# RockChip_RK3588 register map
Vendor: RockChip Electronics Co., Ltd.; Series: RK3588; File version: 0.1
Registers are 32-bit, read-write, no defined reset value unless marked. A register's access mark holds for its fields unless they carry their own. Offsets are from the block's base; [hi:lo] are bit positions; {n}, {i} and the like mark numbered series.

## GRF_DSU
Base 0xFD598000
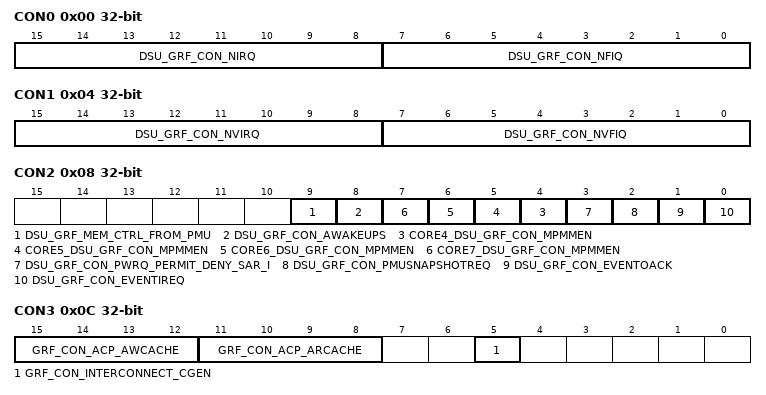
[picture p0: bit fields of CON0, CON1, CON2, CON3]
0x00 CON0 — DSU Control Register 0
  [15:8] DSU_GRF_CON_NIRQ — GRF generate a nirq for each core, for debug usage only
  [7:0] DSU_GRF_CON_NFIQ — GRF generate a nifq for each core, for debug usage only
0x04 CON1 — DSU Control Register 1
  [15:8] DSU_GRF_CON_NVIRQ — GRF generate a nvirq for each core, for debug usage only
  [7:0] DSU_GRF_CON_NVFIQ — GRF generate a nvifq for each core, for debug usage only
0x08 CON2 — DSU Control Register 2
  [9] DSU_GRF_MEM_CTRL_FROM_PMU
    1=PMU (Dsu mem cfg driven by pmu); 0=GRF (Dsu mem cfg driven by grf)
  [8] DSU_GRF_CON_AWAKEUPS
    1=WAKE (Wake acp slave interface); 0=DONT_WAKE (Not wake acp)
  [n] CORE{n}_DSU_GRF_CON_MPMMEN (n=4..7)
    1=ENABLE (Enable max power control for A76); 0=DISABLE
  [3] DSU_GRF_CON_PWRQ_PERMIT_DENY_SAR_I
    1=DENY (Stream adb400 will deny a power request); 0=ACCEPT (Stream adb400 will accept a power request)
  [2] DSU_GRF_CON_PMUSNAPSHOTREQ
    1=SEND (Send a pmu snapshot request to DSU); 0=DONT_SEND (Not send)
  [1] DSU_GRF_CON_EVENTOACK
    1=SEND (Send evento acknowledge to DSU); 0=DONT_SEND (Not send)
  [0] DSU_GRF_CON_EVENTIREQ
    1=SEND (Send eventi request to DSU); 0=DONT_SEND (Not send)
0x0C CON3 — DSU Control Register 3
  [15:12] GRF_CON_ACP_AWCACHE — Awcache control bit for acp
  [11:8] GRF_CON_ACP_ARCACHE — Arcache ctrl bit for acp
  [5] GRF_CON_INTERCONNECT_CGEN
    1=ENABLE (Interconnect clock gate enable); 0=DISABLE
0x10 CON4 — DSU Control Register 4
  [15:0] SYS_GRF_CON_ASTARTMP — Start address of MP master
0x14 CON5 — DSU Control Register 5
  [15:0] SYS_GRF_CON_AENDMP — End address for MP master
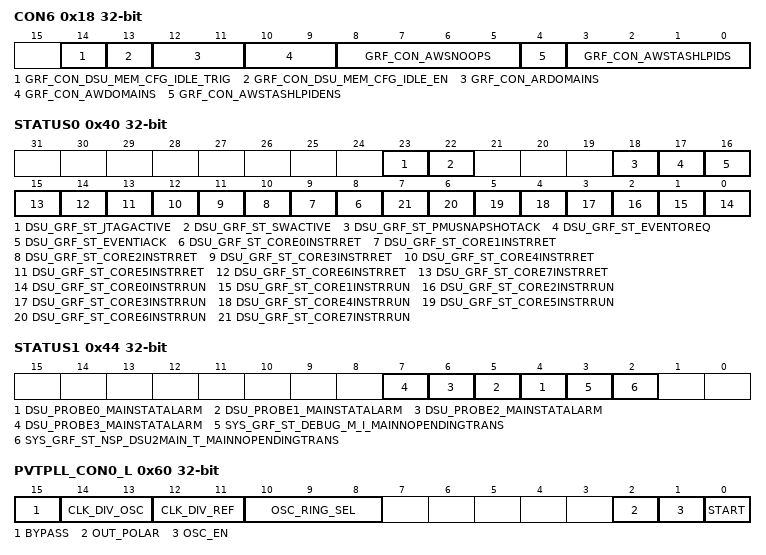
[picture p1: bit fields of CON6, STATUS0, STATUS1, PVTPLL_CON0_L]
0x18 CON6 — DSU Control Register 6
  [14] GRF_CON_DSU_MEM_CFG_IDLE_TRIG — A 0 to 1 trigger of grf_con_dsu_mem_cfg_idle_trig will cause a mem_cfg change when grf_con_dsu_mem_cfg_idle_en equals to 1.
  [13] GRF_CON_DSU_MEM_CFG_IDLE_EN
    0=SW_IMMEDIATELY (Mem_cfg is changed by software immediately); 1=ALL_WFI (Mem_cfg is changed when all cpu in wfi)
  [12:11] GRF_CON_ARDOMAINS — Ardomain control for ACP
  [10:9] GRF_CON_AWDOMAINS — Awdomain control for ACP
  [8:5] GRF_CON_AWSNOOPS — Awsnoop ctrl for ACP
  [4] GRF_CON_AWSTASHLPIDENS — AW stashlpiden for ACP
  [3:0] GRF_CON_AWSTASHLPIDS — AW stashlpid for ACP
0x20 MEM_CFG_HSSPRF_L — Memory Configuration Register For HSSPRF
  [15:0] GRF_DSU_MEM_CFG_HSSPRF_L — bit 0: TEST1 bit 1: TEST_RNM bit 4~2: RM bit 5: WMD bit 7: LS bit 13~12: RA
0x28 MEM_CFG_HSDPRF_L — Memory Configuration Register For HSDPRF Low
  [15:0] GRF_DSU_MEM_CFG_HSSPRF_L — bit 0: TEST1A bit 1: TEST_RNMA bit 5~2: RMA bit 6: WMDA bit 8: LS bit 14~13: RA
0x2C MEM_CFG_HSDPRF_H — Memory Configuration Register For HSDPRF High
  [15:0] GRF_DSU_MEM_CFG_HSSPRF_H — bit 1:TEST1B bit 5~2: RMB
0x30 MEM_CFG_HDSPRA_L — Memory Configuration Register For HDSPRA
  [15:0] GRF_DSU_MEM_CFG_HDSPRA_L — bit 0: TEST1 bit 1: TEST_RNM bit 4~2: RM bit 5: WMD bit 7: LS bit 11~10: WPULSE bit 13~12: RA
0x38 MEM_CFG_UHDDPRF_L — Memory Configuration Register For UHDDPRF
  [15:0] GRF_DSU_MEM_CFG_UHDDPRF_L — bit 0: TEST1 bit 1: TEST_RNM bit 4~2: RM bit 5: WMDA bit 7: LS
0x40 STATUS0 — DSU Status Register 0
  [23] DSU_GRF_ST_JTAGACTIVE ro — JTAG active status.
    1=ACTIVE
  [22] DSU_GRF_ST_SWACTIVE ro — JTAG sw active status.
    1=ACTIVE
  [18] DSU_GRF_ST_PMUSNAPSHOTACK ro — PMU snapshot acknowledge
  [17] DSU_GRF_ST_EVENTOREQ ro — EVENTO request.
  [16] DSU_GRF_ST_EVENTIACK ro — EVENTI acknowledge status
  [n+8] DSU_GRF_ST_CORE{n}INSTRRET ro (n=0..7) — Cpu {n} in retention status
  [n] DSU_GRF_ST_CORE{n}INSTRRUN ro (n=0..7) — Core {n} running status
    1=RUNNING
0x44 STATUS1 — DSU Status Register 1
  [n+4] DSU_PROBE{n}_MAINSTATALARM (n=0..3) — Interconnect probe{n} alarm
  [3] SYS_GRF_ST_DEBUG_M_I_MAINNOPENDINGTRANS ro — Interconnect debug_m no pending translation
  [2] SYS_GRF_ST_NSP_DSU2MAIN_T_MAINNOPENDINGTRANS ro — Interconnect dsu2main no pending translation
0x60 PVTPLL_CON0_L — PVTPLL Control Register 0 Low
  [15] BYPASS
    0=SUPPORT (Support glitch-free frequency conversion.); 1=NOT_SUPPORT
  [14:13] CLK_DIV_OSC — Frequency division factor for osc_clk.
  [12:11] CLK_DIV_REF — Frequency division factor for ref_clk.
  [10:8] OSC_RING_SEL — Oscillator ring channel select.
  [2] OUT_POLAR
    0=OUT_1 (Out=1 when need to increase volt.); 1=OUT_0 (Out=0 when need to increase volt.)
  [1] OSC_EN — Oscillator ring enable.
    1=ENABLE; 0=DISABLE
  [0] START
    1=START (PVTPLL monitor start.)
0x64 PVTPLL_CON0_H — PVTPLL Control Register 0 High
  [5:0] RING_LENGTH_SEL — Oscillator ring inverter length select.
0x70 PVTPLL_CON1 — PVTPLL Control Register 1
  [31:0] CAL_CNT — Target frequency value.
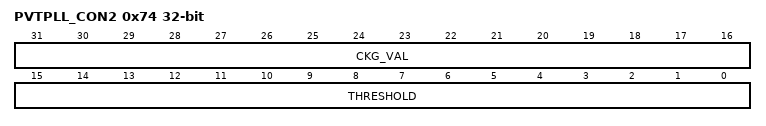
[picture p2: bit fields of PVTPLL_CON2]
0x74 PVTPLL_CON2 — PVTPLL Control Register 2
  [31:16] CKG_VAL — Clock gating interval control count value.
  [15:0] THRESHOLD — Count difference threshold value.
0x78 PVTPLL_CON3 — PVTPLL Control Register 3
  [31:0] REF_CNT — Frequency measurement period setting value.
